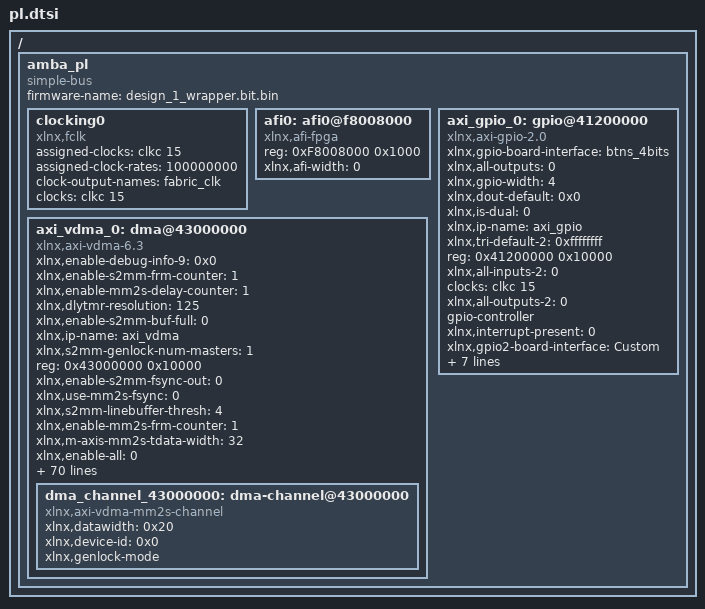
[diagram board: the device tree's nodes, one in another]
/ {
	amba_pl: amba_pl {
		ranges;
		compatible = "simple-bus";
		#address-cells = <1>;
		#size-cells = <1>;
		firmware-name = "design_1_wrapper.bit.bin";
		clocking0: clocking0 {
			compatible = "xlnx,fclk";
			assigned-clocks = <&clkc 15>;
			assigned-clock-rates = <100000000>;
			#clock-cells = <0>;
			clock-output-names = "fabric_clk";
			clocks = <&clkc 15>;
		};
		afi0: afi0@f8008000 {
			status = "okay";
			compatible = "xlnx,afi-fpga";
			#address-cells = <1>;
			reg = <0xF8008000 0x1000>;
			#size-cells = <0>;
			xlnx,afi-width = <0>;
		};
		axi_gpio_0: gpio@41200000 {
			xlnx,gpio-board-interface = "btns_4bits";
			compatible = "xlnx,axi-gpio-2.0" , "xlnx,xps-gpio-1.00.a";
			xlnx,all-outputs = <0>;
			#gpio-cells = <2>;
			xlnx,gpio-width = <4>;
			xlnx,dout-default = <0x0>;
			xlnx,is-dual = <0>;
			xlnx,ip-name = "axi_gpio";
			xlnx,tri-default-2 = <0xffffffff>;
			reg = <0x41200000 0x10000>;
			xlnx,all-inputs-2 = <0>;
			clocks = <&clkc 15>;
			xlnx,all-outputs-2 = <0>;
			gpio-controller;
			xlnx,interrupt-present = <0>;
			xlnx,gpio2-board-interface = "Custom";
			xlnx,edk-iptype = "PERIPHERAL";
			xlnx,dout-default-2 = <0x0>;
			status = "okay";
			xlnx,gpio2-width = <32>;
			clock-names = "s_axi_aclk";
			xlnx,use-board-flow;
			xlnx,tri-default = <0xffffffff>;
			xlnx,name = "axi_gpio_0";
			xlnx,all-inputs = <1>;
		};
		axi_vdma_0: dma@43000000 {
			xlnx,enable-debug-info-9 = <0x0>;
			xlnx,enable-s2mm-frm-counter = <1>;
			xlnx,enable-mm2s-delay-counter = <1>;
			xlnx,dlytmr-resolution = <125>;
			xlnx,enable-s2mm-buf-full = <0>;
			xlnx,ip-name = "axi_vdma";
			xlnx,s2mm-genlock-num-masters = <1>;
			reg = <0x43000000 0x10000>;
			xlnx,enable-s2mm-fsync-out = <0>;
			xlnx,use-mm2s-fsync = <0>;
			xlnx,s2mm-linebuffer-thresh = <4>;
			xlnx,enable-mm2s-frm-counter = <1>;
			xlnx,m-axis-mm2s-tdata-width = <32>;
			xlnx,enable-all = <0>;
			xlnx,dynamic-resolution = <1>;
			xlnx,enable-s2mm-rst-out = <0>;
			xlnx,s2mm-sof-enable = <0x1>;
			xlnx,mm2s-genlock-num-masters = <1>;
			xlnx,enable-mm2s-fsync-out = <0>;
			xlnx,mm2s-linebuffer-thresh = <4>;
			compatible = "xlnx,axi-vdma-6.3" , "xlnx,axi-vdma-1.00.a";
			xlnx,enable-tstvec = <0>;
			xlnx,s2mm-max-burst-length = <8>;
			xlnx,enable-mm2s-rst-out = <0>;
			xlnx,mm2s-sof-enable = <1>;
			xlnx,include-s2mm-dre = <0x0>;
			xlnx,enable-s2mm-frmstr-reg = <0>;
			xlnx,m-axi-s2mm-data-width = <64>;
			xlnx,enable-s2mm-sts-reg = <0>;
			xlnx,mm2s-max-burst-length = <32>;
			status = "okay";
			xlnx,include-mm2s-dre = <0x0>;
			xlnx,name = "axi_vdma_0";
			xlnx,enable-mm2s-frmstr-reg = <0>;
			xlnx,m-axi-mm2s-data-width = <64>;
			xlnx,flush-on-fsync = <0x1>;
			xlnx,include-s2mm-sf = <1>;
			xlnx,single-interface = <0>;
			xlnx,s2mm-linebuffer-depth = <0x200>;
			xlnx,include-s2mm = <0x0>;
			xlnx,addr-width = <32>;
			clocks = <&clkc 15>, <&clkc 15>, <&clkc 15>;
			xlnx,s-axis-s2mm-tdata-width = <32>;
			xlnx,enable-debug-info-10 = <0>;
			xlnx,addrwidth = <0x20>;
			xlnx,enable-debug-info-11 = <0>;
			xlnx,edk-iptype = "PERIPHERAL";
			xlnx,enable-debug-info-12 = <0>;
			xlnx,use-fsync = <1>;
			xlnx,s2mm-genlock-repeat-en = <1>;
			xlnx,enable-debug-info-13 = <0x0>;
			xlnx,enable-vert-flip = <0x0>;
			xlnx,include-mm2s-sf = <0>;
			xlnx,enable-debug-info-14 = <0x1>;
			xlnx,include-internal-genlock = <0x1>;
			clock-names = "m_axi_mm2s_aclk" , "m_axis_mm2s_aclk" , "s_axi_lite_aclk";
			xlnx,enable-debug-info-15 = <0x1>;
			xlnx,mm2s-linebuffer-depth = <0x800>;
			xlnx,include-mm2s = <0x1>;
			xlnx,s2mm-genlock-mode = <0x0>;
			xlnx,flush-fsync = <0x1>;
			xlnx,select-xpm = <0>;
			xlnx,s2mm-data-width = <0x40>;
			xlnx,num-fstores = <0x2>;
			xlnx,enable-s2mm-param-updt = <0>;
			xlnx,enable-vidparam-reads = <0x1>;
			xlnx,mm2s-genlock-repeat-en = <0>;
			xlnx,prmry-is-aclk-async = <0>;
			xlnx,s2mm-tdata-width = <0x20>;
			#dma-cells = <1>;
			xlnx,enable-vidprmtr-reads = <1>;
			xlnx,mm2s-genlock-mode = <0x3>;
			xlnx,enable-debug-info-0 = <0>;
			xlnx,enable-debug-all = <0x0>;
			xlnx,enable-debug-info-1 = <0x0>;
			xlnx,mm2s-data-width = <0x40>;
			xlnx,enable-debug-info-2 = <0>;
			xlnx,enable-mm2s-param-updt = <0>;
			xlnx,enable-debug-info-3 = <0>;
			xlnx,enable-s2mm-delay-counter = <1>;
			xlnx,enable-debug-info-4 = <0>;
			xlnx,enable-debug-info-5 = <0x0>;
			xlnx,mm2s-tdata-width = <0x20>;
			xlnx,enable-debug-info-6 = <0x1>;
			xlnx,enable-debug-info-7 = <0x1>;
			xlnx,use-s2mm-fsync = <2>;
			xlnx,enable-debug-info-8 = <0>;
			xlnx,enable-mm2s-buf-empty = <0>;
			dma_channel_43000000: dma-channel@43000000 {
				xlnx,datawidth = <0x20>;
				xlnx,device-id = <0x0>;
				compatible = "xlnx,axi-vdma-mm2s-channel";
				xlnx,genlock-mode;
			};
		};
	};
};
